# M481_v1 register map
File version: 1.0
Registers are 32-bit, read-write, reset 0x0 unless marked. A register's access mark holds for its fields unless they carry their own. Offsets are from the block's base; [hi:lo] are bit positions; {n}, {i} and the like mark numbered series.

## CURSCAT — PDMA Register Map
Base 0x40008100
{0x0+4i} PDMA_CURSCAT{i} ro reset not defined (i=0..15) — Current Scatter-gather Descriptor Table Address of PDMA Channel n
  [31:0] CURADDR — PDMA Current Description Address (Read Only). This field indicates a 32-bit current external description address of PDMA controller. Note: This field is read only and used for Scatter-Gather mode only to indicate the current external description address.

## DSCT_CTL — PDMA Register Map
Base 0x40008000
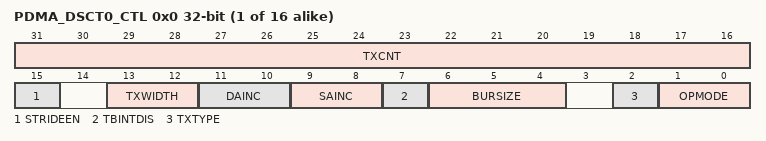
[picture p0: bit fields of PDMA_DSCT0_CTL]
{0x0+0x10*i} PDMA_DSCT{i}_CTL reset not defined (i=0..15) — Descriptor Table Control Register of PDMA Channel n
  [31:16] TXCNT — Transfer Count. The TXCNT represents the required number of PDMA transfer, the real transfer count is (TXCNT + 1); The maximum transfer count is 65536, every transfer may be byte, half-word or word that is dependent on TXWIDTH field. Note: When PDMA finish each transfer data, this field will be decrease immediately.
  [15] STRIDEEN — Stride Mode Enable Bit
    0=Stride transfer mode Disabled; 1=Stride transfer mode Enabled
  [13:12] TXWIDTH — Transfer Width Selection. This field is used for transfer width. Note: The PDMA transfer source address (PDMA_DSCT_SA) and PDMA transfer destination address (PDMA_DSCT_DA) should be alignment under the TXWIDTH selection
    0=One byte (8 bit) is transferred for every operation; 1=One half-word (16 bit) is transferred for every operation; 2=One word (32-bit) is transferred for every operation
  [11:10] DAINC — Destination Address Increment. This field is used to set the destination address increment size. Note: The fixed address function is not supported in memory to memory transfer type.
    3=No increment (fixed address)
  [9:8] SAINC — Source Address Increment. This field is used to set the source address increment size. Note: The fixed address function is not supported in memory to memory transfer type.
    3=No increment (fixed address)
  [7] TBINTDIS — Table Interrupt Disable Bit. This field can be used to decide whether to enable table interrupt or not. If the TBINTDIS bit is enabled it will not generates TDIFn(PDMA_TDSTS[15:0]) when PDMA controller finishes transfer task. Note: This function only for scatter-gather mode.
    0=Table interrupt Enabled; 1=Table interrupt Disabled
  [6:4] BURSIZE — Burst Size. Note: This field is only useful in burst transfer type.
    0=128 Transfers; 1=64 Transfers; 2=32 Transfers; 3=16 Transfers; 4=8 Transfers; 5=4 Transfers; 6=2 Transfers; 7=1 Transfers
  [2] TXTYPE — Transfer Type
    0=Burst transfer type; 1=Single transfer type
  [1:0] OPMODE — PDMA Operation Mode Selection. Note: Before filling new transfer task in the Descriptor Table, user must check the PDMA_INTSTS[1] to make sure the curren task is complete.
    0=Idle state: Channel is stopped or this table is complete, when PDMA finish channel table task, OPMODE will be cleared to idle state automatically; 1=Basic mode: The descriptor table only has one task. When this task is finished, the PDMA_INTSTS[1] will be asserted; 2=Scatter-Gather mode: When operating in this mode, user must give the next descriptor table address in PDMA_DSCT_NEXT register; PDMA controller will ignore this task, then load the next task to execute

## DSCT_DA — PDMA Register Map
Base 0x40008008
{0x0+0x10*i} PDMA_DSCT{i}_DA reset not defined (i=0..15) — Destination Address Register of PDMA Channel n
  [31:0] DA — PDMA Transfer Destination Address. This field indicates a 32-bit destination address of PDMA controller.

## DSCT_NEXT — PDMA Register Map
Base 0x4000800C
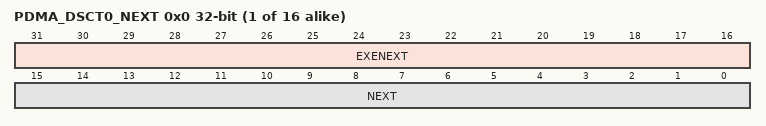
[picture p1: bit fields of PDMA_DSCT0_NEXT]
{0x0+0x10*i} PDMA_DSCT{i}_NEXT reset not defined (i=0..15) — Next Scatter-gather Descriptor Table Offset Address of PDMA Channel n
  [31:16] EXENEXT — PDMA Execution Next Descriptor Table Offset. This field indicates the offset of next descriptor table address of current execution descriptor table in system memory. Note: write operation is useless in this field.
  [15:0] NEXT — PDMA Next Descriptor Table Offset. This field indicates the offset of the next descriptor table address in system memory. Write Operation: If the system memory based address is 0x2000_0000 (PDMA_SCATBA), and the next descriptor table is start from 0x2000_0100, then this field must fill in 0x0100. Read Operation: When operating in scatter-gather mode, the last two bits NEXT[1:0] will become reserved, and indicate the first next address of system memory. Note 1: The descriptor table address must be word boundary. Note 2: Before filled transfer task in the descriptor table, user must check if the descriptor table is complete.
